# FIELDACTION register map
Vendor: Test; File version: 1.0
Field-level readAction fixture
CPU: CM0
Registers are 32-bit, access not given, no defined reset value unless marked. A register's access mark holds for its fields unless they carry their own. Offsets are from the block's base; lines under a group give offsets from that group; [hi:lo] are bit positions; {n}, {i} and the like mark numbered series; 'fields as' and 'values as' point back to an identical list; <NAME> marks a mode.

## Memory map
0x40010000 P

## P
Base 0x40010000
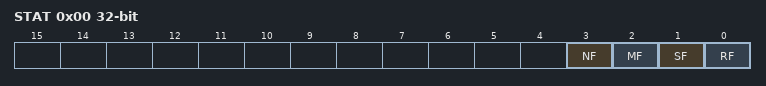
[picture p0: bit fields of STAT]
0x00 STAT
  [3] NF — 普通字段
  [2] MF read-modifies — 读取时修改
  [1] SF read-sets — 读取后置位
  [0] RF read-clears — 读取后清零
0x04 PLAIN_STAT
  [0] BIT0
